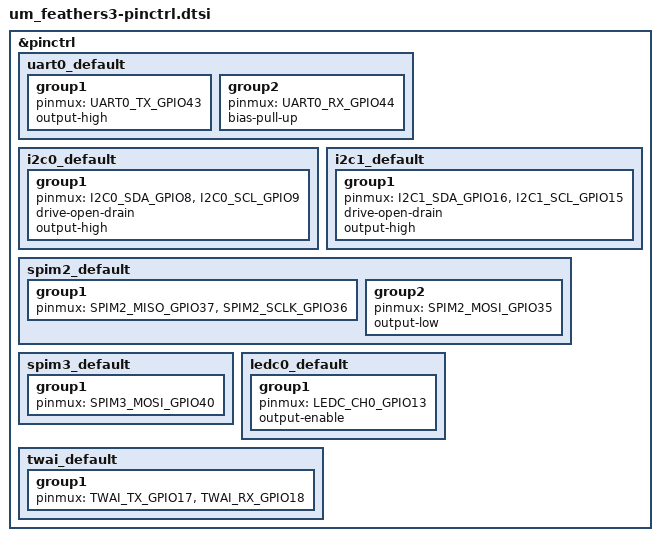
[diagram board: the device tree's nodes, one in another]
/*
 * SPDX-FileCopyrightText: Copyright (c) 2024 Espressif Systems (Shanghai) Co., Ltd.
 * SPDX-FileCopyrightText: Copyright (c) 2024 Leon Rinkel <leon@rinkel.me>
 * SPDX-FileCopyrightText: Copyright (c) 2026 Perry Naseck, MIT Media Lab <pnaseck@media.mit.edu>
 * SPDX-License-Identifier: Apache-2.0
 */

#include <zephyr/dt-bindings/pinctrl/esp32s3-pinctrl.h>

&pinctrl {
	uart0_default: uart0_default {
		group1 {
			pinmux = <UART0_TX_GPIO43>;
			output-high;
		};

		group2 {
			pinmux = <UART0_RX_GPIO44>;
			bias-pull-up;
		};
	};

	i2c0_default: i2c0_default {
		group1 {
			pinmux = <I2C0_SDA_GPIO8>,
				 <I2C0_SCL_GPIO9>;
			drive-open-drain;
			output-high;
		};
	};

	i2c1_default: i2c1_default {
		group1 {
			pinmux = <I2C1_SDA_GPIO16>,
				 <I2C1_SCL_GPIO15>;
			drive-open-drain;
			output-high;
		};
	};

	spim2_default: spim2_default {
		group1 {
			pinmux = <SPIM2_MISO_GPIO37>,
				 <SPIM2_SCLK_GPIO36>;
		};

		group2 {
			pinmux = <SPIM2_MOSI_GPIO35>;
			output-low;
		};
	};

	spim3_default: spim3_default {
		group1 {
			pinmux = <SPIM3_MOSI_GPIO40>;
		};
	};

	ledc0_default: ledc0_default {
		group1 {
			pinmux = <LEDC_CH0_GPIO13>;
			output-enable;
		};
	};

	twai_default: twai_default {
		group1 {
			pinmux = <TWAI_TX_GPIO17>,
				 <TWAI_RX_GPIO18>;
		};
	};
};
